# PIC16F1619 register map
File version: 1.0
Registers are 8-bit, read-write, reset 0x0 unless marked. A register's access mark holds for its fields unless they carry their own. Offsets are from the block's base; [hi:lo] are bit positions; {n}, {i} and the like mark numbered series.

## OTHER — Other registers
Base 0x0080001A
0x00 T2TMR — T2TMR, data address 0x01a
  [7:0] TMR
0x01 T2PR reset 0xFF — T2PR, data address 0x01b
  [7:0] PR
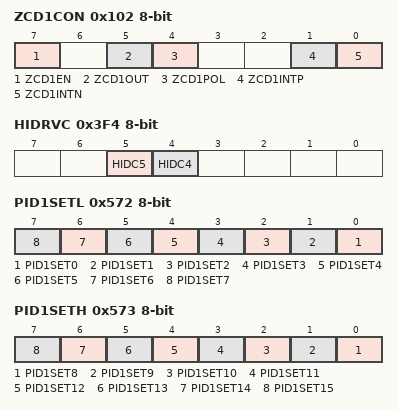
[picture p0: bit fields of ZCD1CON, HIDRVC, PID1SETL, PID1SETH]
0x102 ZCD1CON (reset mask 0x93) — ZCD1CON, data address 0x11c
  [7] ZCD1EN, [5] ZCD1OUT, [4] ZCD1POL, [1] ZCD1INTP, [0] ZCD1INTN
0x3F4 HIDRVC — HIDRVC, data address 0x40e
  [5] HIDC5, [4] HIDC4
0x3F9 T4TMR — T4TMR, data address 0x413
  [7:0] TMR
0x3FA T4PR reset 0xFF — T4PR, data address 0x414
  [7:0] PR
0x400 T6TMR — T6TMR, data address 0x41a
  [7:0] TMR
0x401 T6PR reset 0xFF — T6PR, data address 0x41b
  [7:0] PR
0x572 PID1SETL — PID1SETL, data address 0x58c
  [n] PID1SET{n} (n=0..7)
0x573 PID1SETH — PID1SETH, data address 0x58d
  [n-8] PID1SET{n} (n=8..15)
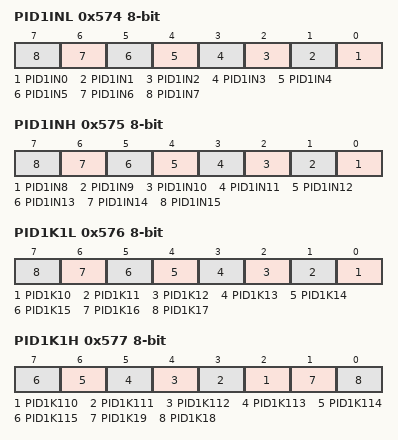
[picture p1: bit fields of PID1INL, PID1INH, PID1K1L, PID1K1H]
0x574 PID1INL reset not defined — PID1INL, data address 0x58e
  [n] PID1IN{n} (n=0..7)
0x575 PID1INH reset not defined — PID1INH, data address 0x58f
  [n-8] PID1IN{n} (n=8..15)
0x576 PID1K1L reset not defined — PID1K1L, data address 0x590
  [n-10] PID1K{n} (n=10..17)
0x577 PID1K1H reset not defined — PID1K1H, data address 0x591
  [n-108] PID1K{n} (n=110..115), [1] PID1K19, [0] PID1K18
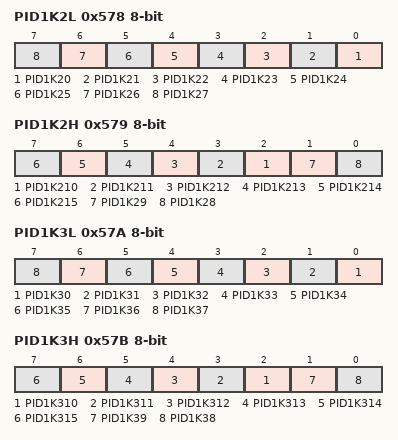
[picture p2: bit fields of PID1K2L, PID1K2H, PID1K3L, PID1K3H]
0x578 PID1K2L reset not defined — PID1K2L, data address 0x592
  [n-20] PID1K{n} (n=20..27)
0x579 PID1K2H reset not defined — PID1K2H, data address 0x593
  [n-208] PID1K{n} (n=210..215), [1] PID1K29, [0] PID1K28
0x57A PID1K3L reset not defined — PID1K3L, data address 0x594
  [n-30] PID1K{n} (n=30..37)
0x57B PID1K3H reset not defined — PID1K3H, data address 0x595
  [n-308] PID1K{n} (n=310..315), [1] PID1K39, [0] PID1K38
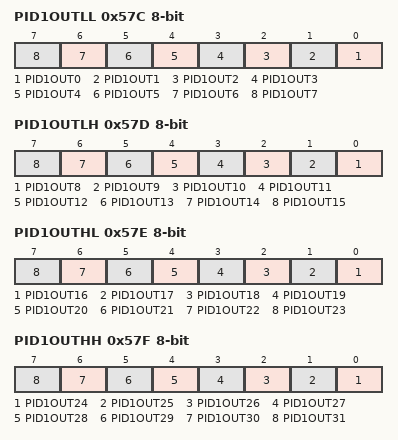
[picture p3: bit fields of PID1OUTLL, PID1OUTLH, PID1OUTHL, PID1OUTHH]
0x57C PID1OUTLL — PID1OUTLL, data address 0x596
  [n] PID1OUT{n} (n=0..7)
0x57D PID1OUTLH — PID1OUTLH, data address 0x597
  [n-8] PID1OUT{n} (n=8..15)
0x57E PID1OUTHL — PID1OUTHL, data address 0x598
  [n-16] PID1OUT{n} (n=16..23)
0x57F PID1OUTHH — PID1OUTHH, data address 0x599
  [n-24] PID1OUT{n} (n=24..31)
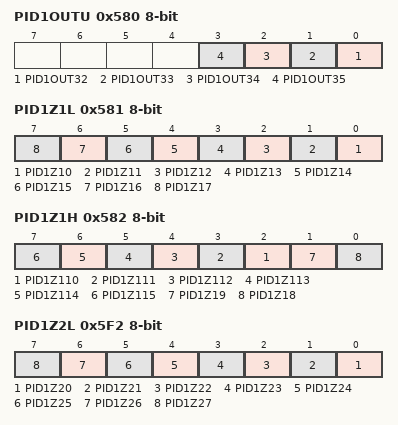
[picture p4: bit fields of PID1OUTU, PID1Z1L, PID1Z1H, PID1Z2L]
0x580 PID1OUTU — PID1OUTU, data address 0x59a
  [n-32] PID1OUT{n} (n=32..35)
0x581 PID1Z1L — PID1Z1L, data address 0x59b
  [n-10] PID1Z{n} (n=10..17)
0x582 PID1Z1H — PID1Z1H, data address 0x59c
  [n-108] PID1Z{n} (n=110..115), [1] PID1Z19, [0] PID1Z18
0x583 PID1Z1U — PID1Z1U, data address 0x59d
  [0] PID1Z116
0x5F2 PID1Z2L — PID1Z2L, data address 0x60c
  [n-20] PID1Z{n} (n=20..27)
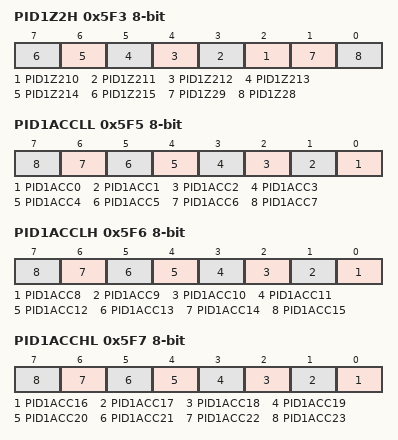
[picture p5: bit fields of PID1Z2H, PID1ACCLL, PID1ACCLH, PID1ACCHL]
0x5F3 PID1Z2H — PID1Z2H, data address 0x60d
  [n-208] PID1Z{n} (n=210..215), [1] PID1Z29, [0] PID1Z28
0x5F4 PID1Z2U — PID1Z2U, data address 0x60e
  [0] PID1Z216
0x5F5 PID1ACCLL — PID1ACCLL, data address 0x60f
  [n] PID1ACC{n} (n=0..7)
0x5F6 PID1ACCLH — PID1ACCLH, data address 0x610
  [n-8] PID1ACC{n} (n=8..15)
0x5F7 PID1ACCHL — PID1ACCHL, data address 0x611
  [n-16] PID1ACC{n} (n=16..23)
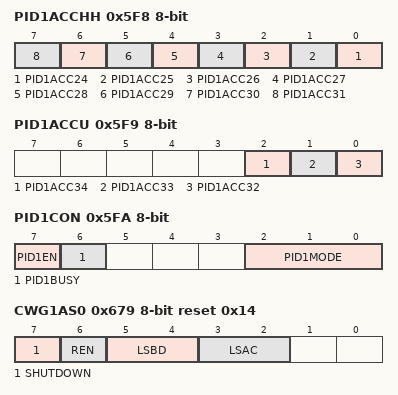
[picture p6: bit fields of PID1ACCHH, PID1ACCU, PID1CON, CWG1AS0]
0x5F8 PID1ACCHH — PID1ACCHH, data address 0x612
  [n-24] PID1ACC{n} (n=24..31)
0x5F9 PID1ACCU — PID1ACCU, data address 0x613
  [2] PID1ACC34, [1] PID1ACC33, [0] PID1ACC32
0x5FA PID1CON — PID1CON, data address 0x614
  [7] PID1EN, [6] PID1BUSY, [2:0] PID1MODE
0x677 CWG1DBR — CWG1DBR, data address 0x691
  [5:0] DBR
0x678 CWG1DBF — CWG1DBF, data address 0x692
  [5:0] DBF
0x679 CWG1AS0 reset 0x14 — CWG1AS0, data address 0x693
  [7] SHUTDOWN, [6] REN, [5:4] LSBD, [3:2] LSAC
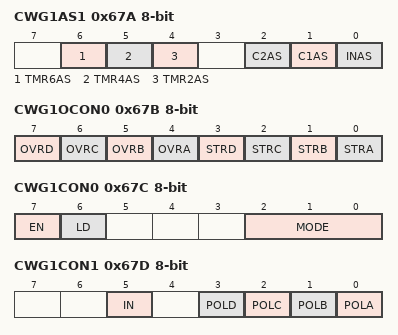
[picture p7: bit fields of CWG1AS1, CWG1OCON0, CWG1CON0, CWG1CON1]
0x67A CWG1AS1 — CWG1AS1, data address 0x694
  [6] TMR6AS, [5] TMR4AS, [4] TMR2AS, [2] C2AS, [1] C1AS, [0] INAS
0x67B CWG1OCON0 — CWG1OCON0, data address 0x695
  [7] OVRD, [6] OVRC, [5] OVRB, [4] OVRA, [3] STRD, [2] STRC, [1] STRB, [0] STRA
0x67C CWG1CON0 — CWG1CON0, data address 0x696
  [7] EN, [6] LD, [2:0] MODE
0x67D CWG1CON1 — CWG1CON1, data address 0x697
  [5] IN, [3] POLD, [2] POLC, [1] POLB, [0] POLA
0x67F CWG1CLKCON — CWG1CLKCON, data address 0x699
  [0] CS
0x680 CWG1ISM (reset mask 0xF) — CWG1ISM, data address 0x69a
  [7:0] IS
0x6F9 WDTPSL — WDTPSL, data address 0x713
  [7:0] PSCNT
0x6FA WDTPSH — WDTPSH, data address 0x714
  [7:0] PSCNT
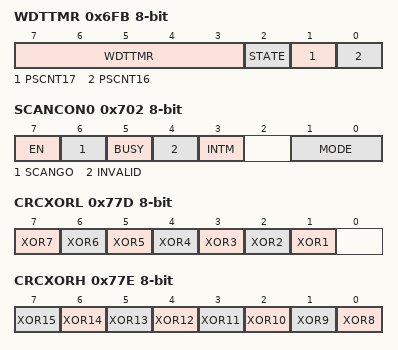
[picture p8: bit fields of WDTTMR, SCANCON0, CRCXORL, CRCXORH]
0x6FB WDTTMR (reset mask 0x7) — WDTTMR, data address 0x715
  [7:3] WDTTMR, [2] STATE, [1] PSCNT17, [0] PSCNT16
0x6FE SCANLADRL — SCANLADRL, data address 0x718
  [7:0] LADR
0x6FF SCANLADRH — SCANLADRH, data address 0x719
  [7:0] LADR
0x700 SCANHADRL reset 0xFF — SCANHADRL, data address 0x71a
  [7:0] HADR
0x701 SCANHADRH reset 0xFF — SCANHADRH, data address 0x71b
  [7:0] HADR
0x702 SCANCON0 — SCANCON0, data address 0x71c
  [7] EN, [6] SCANGO, [5] BUSY, [4] INVALID, [3] INTM, [1:0] MODE
0x703 SCANTRIG (reset mask 0xF) — SCANTRIG, data address 0x71d
  [7:0] TSEL
0x777 CRCDATL reset not defined — CRCDATL, data address 0x791
  [7:0] DAT
0x778 CRCDATH reset not defined — CRCDATH, data address 0x792
  [7:0] DAT
0x779 CRCACCL — CRCACCL, data address 0x793
  [7:0] ACC
0x77A CRCACCH — CRCACCH, data address 0x794
  [7:0] ACC
0x77B CRCSHIFTL — CRCSHIFTL, data address 0x795
  [7:0] SHIFT
0x77C CRCSHIFTH — CRCSHIFTH, data address 0x796
  [7:0] SHIFT
0x77D CRCXORL reset not defined — CRCXORL, data address 0x797
  [n] XOR{n} (n=1..7)
0x77E CRCXORH reset not defined — CRCXORH, data address 0x798
  [n-8] XOR{n} (n=8..15)
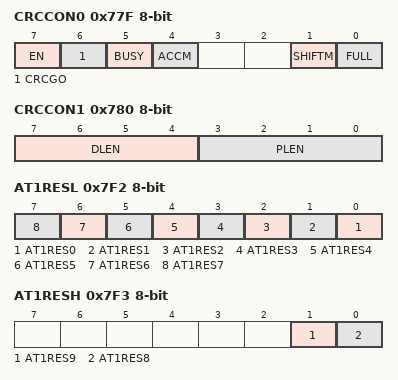
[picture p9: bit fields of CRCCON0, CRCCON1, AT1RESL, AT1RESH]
0x77F CRCCON0 — CRCCON0, data address 0x799
  [7] EN, [6] CRCGO, [5] BUSY, [4] ACCM, [1] SHIFTM, [0] FULL
0x780 CRCCON1 — CRCCON1, data address 0x79a
  [7:4] DLEN, [3:0] PLEN
0x7F2 AT1RESL reset not defined — AT1RESL, data address 0x80c
  [n] AT1RES{n} (n=0..7)
0x7F3 AT1RESH reset not defined — AT1RESH, data address 0x80d
  [1] AT1RES9, [0] AT1RES8
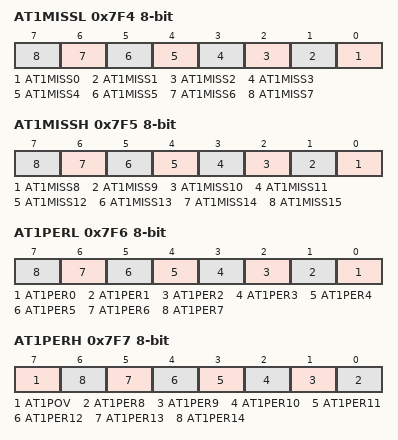
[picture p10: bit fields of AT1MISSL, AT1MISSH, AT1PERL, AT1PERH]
0x7F4 AT1MISSL reset not defined — AT1MISSL, data address 0x80e
  [n] AT1MISS{n} (n=0..7)
0x7F5 AT1MISSH reset not defined — AT1MISSH, data address 0x80f
  [n-8] AT1MISS{n} (n=8..15)
0x7F6 AT1PERL reset not defined — AT1PERL, data address 0x810
  [n] AT1PER{n} (n=0..7)
0x7F7 AT1PERH reset not defined — AT1PERH, data address 0x811
  [7] AT1POV, [n-8] AT1PER{n} (n=8..14)
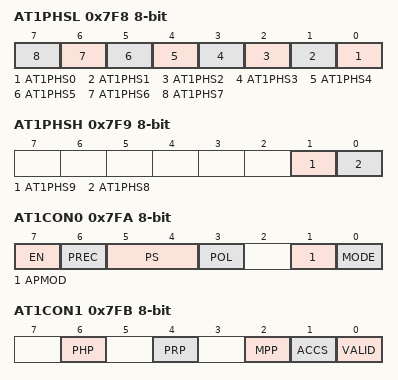
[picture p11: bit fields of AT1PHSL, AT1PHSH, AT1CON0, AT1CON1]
0x7F8 AT1PHSL reset not defined — AT1PHSL, data address 0x812
  [n] AT1PHS{n} (n=0..7)
0x7F9 AT1PHSH reset not defined — AT1PHSH, data address 0x813
  [1] AT1PHS9, [0] AT1PHS8
0x7FA AT1CON0 (reset mask 0xBB) — AT1CON0, data address 0x814
  [7] EN, [6] PREC, [5:4] PS, [3] POL, [1] APMOD, [0] MODE
0x7FB AT1CON1 — AT1CON1, data address 0x815
  [6] PHP, [4] PRP, [2] MPP, [1] ACCS, [0] VALID
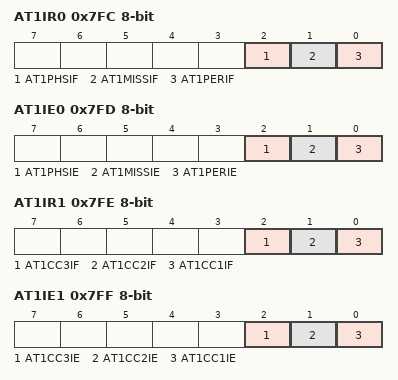
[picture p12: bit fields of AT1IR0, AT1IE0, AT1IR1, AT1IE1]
0x7FC AT1IR0 — AT1IR0, data address 0x816
  [2] AT1PHSIF, [1] AT1MISSIF, [0] AT1PERIF
0x7FD AT1IE0 — AT1IE0, data address 0x817
  [2] AT1PHSIE, [1] AT1MISSIE, [0] AT1PERIE
0x7FE AT1IR1 — AT1IR1, data address 0x818
  [2] AT1CC3IF, [1] AT1CC2IF, [0] AT1CC1IF
0x7FF AT1IE1 — AT1IE1, data address 0x819
  [2] AT1CC3IE, [1] AT1CC2IE, [0] AT1CC1IE
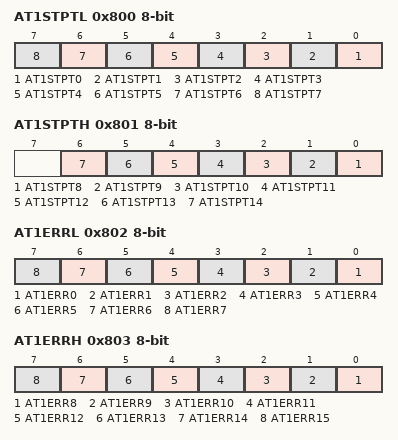
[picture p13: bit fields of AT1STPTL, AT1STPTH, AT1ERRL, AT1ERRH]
0x800 AT1STPTL reset not defined — AT1STPTL, data address 0x81a
  [n] AT1STPT{n} (n=0..7)
0x801 AT1STPTH reset not defined — AT1STPTH, data address 0x81b
  [n-8] AT1STPT{n} (n=8..14)
0x802 AT1ERRL reset not defined — AT1ERRL, data address 0x81c
  [n] AT1ERR{n} (n=0..7)
0x803 AT1ERRH reset not defined — AT1ERRH, data address 0x81d
  [n-8] AT1ERR{n} (n=8..15)
0x872 AT1CLK — AT1CLK, data address 0x88c
  [0] CS
0x873 AT1SIG — AT1SIG, data address 0x88d
  [2:0] SSEL
0x874 AT1CSEL1 — AT1CSEL1, data address 0x88e
  [2:0] CP1S
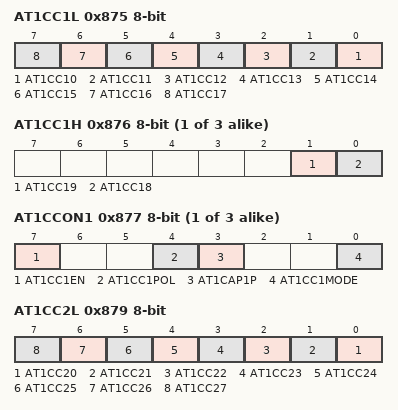
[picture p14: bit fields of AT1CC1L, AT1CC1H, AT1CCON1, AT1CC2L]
0x875 AT1CC1L — AT1CC1L, data address 0x88f
  [n-10] AT1CC{n} (n=10..17)
{0x872+4i} AT1CC{i}H (i=1..3) — AT1CC{i}H, data address {0x88C+4i}
  [1] AT1CC{10i+9}, [0] AT1CC{10i+8}
{0x873+4i} AT1CCON{i} (i=1..3) — AT1CCON{i}, data address {0x88D+4i}
  [7] AT1CC{i}EN, [4] AT1CC{i}POL, [3] AT1CAP{i}P, [0] AT1CC{i}MODE
0x878 AT1CSEL2 — AT1CSEL2, data address 0x892
  [2:0] AT1CP2S
0x879 AT1CC2L — AT1CC2L, data address 0x893
  [n-20] AT1CC{n} (n=20..27)
0x87C AT1CSEL3 — AT1CSEL3, data address 0x896
  [2:0] AT1CP3S
0x87D AT1CC3L — AT1CC3L, data address 0x897
  [n-30] AT1CC{n} (n=30..37)
0xD72 SMT1TMRL — SMT1TMRL, data address 0xd8c
  [7:0] SMT1TMR
0xD73 SMT1TMRH — SMT1TMRH, data address 0xd8d
  [7:0] SMT1TMR
0xD74 SMT1TMRU — SMT1TMRU, data address 0xd8e
  [7:0] SMT1TMR
0xD75 SMT1CPRL reset not defined — SMT1CPRL, data address 0xd8f
  [7:0] SMT1CPR
0xD76 SMT1CPRH reset not defined — SMT1CPRH, data address 0xd90
  [7:0] SMT1CPR
0xD77 SMT1CPRU reset not defined — SMT1CPRU, data address 0xd91
  [7:0] SMT1CPR
0xD78 SMT1CPWL reset not defined — SMT1CPWL, data address 0xd92
  [7:0] SMT1CPW
0xD79 SMT1CPWH reset not defined — SMT1CPWH, data address 0xd93
  [7:0] SMT1CPW
0xD7A SMT1CPWU reset not defined — SMT1CPWU, data address 0xd94
  [7:0] SMT1CPW
0xD7B SMT1PRL reset 0xFF — SMT1PRL, data address 0xd95
  [7:0] SMT1PR
0xD7C SMT1PRH reset 0xFF — SMT1PRH, data address 0xd96
  [7:0] SMT1PR
0xD7D SMT1PRU reset 0xFF — SMT1PRU, data address 0xd97
  [7:0] SMT1PR
0xD7E SMT1CON0 — SMT1CON0, data address 0xd98
  [7] EN, [5] STP, [4] WPOL, [3] SPOL, [2] CPOL, [1:0] SMT1PS
0xD7F SMT1CON1 — SMT1CON1, data address 0xd99
  [7] SMT1GO, [6] REPEAT, [3:0] MODE
0xD80 SMT1STAT — SMT1STAT, data address 0xd9a
  [7] CPRUP, [6] CPWUP, [5] RST, [2] TS, [1] WS, [0] AS
0xD81 SMT1CLK (reset mask 0x7) — SMT1CLK, data address 0xd9b
  [7:0] CSEL
0xD82 SMT1SIG (reset mask 0x1F) — SMT1SIG, data address 0xd9c
  [7:0] SSEL
0xD83 SMT1WIN (reset mask 0x1F) — SMT1WIN, data address 0xd9d
  [7:0] WSEL
0xD84 SMT2TMRL — SMT2TMRL, data address 0xd9e
  [7:0] SMT2TMR
0xD85 SMT2TMRH — SMT2TMRH, data address 0xd9f
  [7:0] SMT2TMR
0xD86 SMT2TMRU — SMT2TMRU, data address 0xda0
  [7:0] SMT2TMR
0xD87 SMT2CPRL reset not defined — SMT2CPRL, data address 0xda1
  [7:0] SMT2CPR
0xD88 SMT2CPRH reset not defined — SMT2CPRH, data address 0xda2
  [7:0] SMT2CPR
0xD89 SMT2CPRU reset not defined — SMT2CPRU, data address 0xda3
  [7:0] SMT2CPR
0xD8A SMT2CPWL reset not defined — SMT2CPWL, data address 0xda4
  [7:0] SMT2CPW
0xD8B SMT2CPWH reset not defined — SMT2CPWH, data address 0xda5
  [7:0] SMT2CPW
0xD8C SMT2CPWU reset not defined — SMT2CPWU, data address 0xda6
  [7:0] SMT2CPW
0xD8D SMT2PRL reset 0xFF — SMT2PRL, data address 0xda7
  [7:0] SMT2PR
0xD8E SMT2PRH reset 0xFF — SMT2PRH, data address 0xda8
  [7:0] SMT2PR
0xD8F SMT2PRU reset 0xFF — SMT2PRU, data address 0xda9
  [7:0] SMT2PR
0xD90 SMT2CON0 — SMT2CON0, data address 0xdaa
  [7] EN, [5] STP, [4] WPOL, [3] SPOL, [2] CPOL, [1:0] SMT2PS
0xD91 SMT2CON1 — SMT2CON1, data address 0xdab
  [7] SMT2GO, [6] REPEAT, [3:0] MODE
0xD92 SMT2STAT — SMT2STAT, data address 0xdac
  [7] CPRUP, [6] CPWUP, [5] RST, [2] TS, [1] WS, [0] AS
0xD93 SMT2CLK (reset mask 0x7) — SMT2CLK, data address 0xdad
  [7:0] CSEL
0xD94 SMT2SIG (reset mask 0x1F) — SMT2SIG, data address 0xdae
  [7:0] SSEL
0xD95 SMT2WIN (reset mask 0x1F) — SMT2WIN, data address 0xdaf
  [7:0] WSEL
0xEF5 CLCDATA — CLCDATA, data address 0xf0f
  [n-1] MLC{n}OUT (n=1..4)
{0xEEC+0xA*i} CLC{i}CON (i=1..4) — CLC{i}CON, data address {0xF06+0xA*i}
  [7] LC{i}EN, [5] LC{i}OUT, [4] LC{i}INTP, [3] LC{i}INTN, [2:0] LC{i}MODE
{0xEED+0xA*i} CLC{i}POL (reset mask 0x80) (i=1..4) — CLC{i}POL, data address {0xF07+0xA*i}
  [7] LC{i}POL, [n-1] LC{i}G{n}POL (n=1..4)
{0xEEE+0xA*i} CLC{i}SEL0 reset not defined (i=1..4) — CLC{i}SEL0, data address {0xF08+0xA*i}
  [n] LC{i}D1S{n} (n=0..5)
{0xEEF+0xA*i} CLC{i}SEL1 reset not defined (i=1..4) — CLC{i}SEL1, data address {0xF09+0xA*i}
  [n] LC{i}D2S{n} (n=0..5)
{0xEF0+0xA*i} CLC{i}SEL2 reset not defined (i=1..4) — CLC{i}SEL2, data address {0xF0A+0xA*i}
  [n] LC{i}D3S{n} (n=0..5)
{0xEF1+0xA*i} CLC{i}SEL3 reset not defined (i=1..4) — CLC{i}SEL3, data address {0xF0B+0xA*i}
  [n] LC{i}D4S{n} (n=0..5)
{0xEF2+0xA*i} CLC{i}GLS0 reset not defined (i=1..4) — CLC{i}GLS0, data address {0xF0C+0xA*i}
  [2n-1] LC{i}G1D{n}T (n=1..4), [2n-2] LC{i}G1D{n}N (n=1..4)
{0xEF3+0xA*i} CLC{i}GLS1 reset not defined (i=1..4) — CLC{i}GLS1, data address {0xF0D+0xA*i}
  [2n-1] LC{i}G2D{n}T (n=1..4), [2n-2] LC{i}G2D{n}N (n=1..4)
{0xEF4+0xA*i} CLC{i}GLS2 reset not defined (i=1..4) — CLC{i}GLS2, data address {0xF0E+0xA*i}
  [2n-1] LC{i}G3D{n}T (n=1..4), [2n-2] LC{i}G3D{n}N (n=1..4)
{0xEF5+0xA*i} CLC{i}GLS3 reset not defined (i=1..4) — CLC{i}GLS3, data address {0xF0F+0xA*i}
  [2n-1] LC{i}G4D{n}T (n=1..4), [2n-2] LC{i}G4D{n}N (n=1..4)
